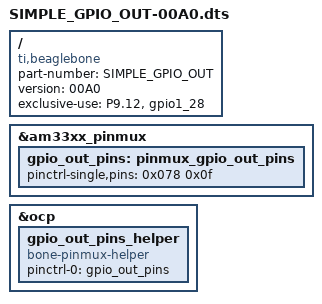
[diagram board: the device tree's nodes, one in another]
/*
 * Copyright (C) 2013
 *
 * This program is free software; you can redistribute it and/or modify
 * it under the terms of the GNU General Public License version 2 as
 * published by the Free Software Foundation.
 *
 * Simple GPIO overlay example: Configures pin P9.12 (gpio1_28) as an output pin
 */
/dts-v1/;
/plugin/;

/ {
    compatible = "ti,beaglebone", "ti,beaglebone-black";

    /* identification */
    part-number = "SIMPLE_GPIO_OUT";
    version = "00A0";

    /* state the resources this cape uses */
    exclusive-use =
        /* the pin header uses */
        "P9.12",/* conf_gpmc_ben1 gpio1_28 */
        /* the hardware ip uses */
        "gpio1_28";

    fragment@0 {
        /* pin mux offsets given to the am33xx_pinmux target are expected to be
           rooted at the base from where the conf_<module>_<pin> register starts
           which is 0x800. Therefore, 0x800 should be subtracted from the values
           given in the technical reference manual */
        target = <&am33xx_pinmux>;
        __overlay__ {
            gpio_out_pins: pinmux_gpio_out_pins {
                pinctrl-single,pins = <
                    0x078 0x0f /* P9.12, conf_gpmc_ben1, gpio1_28  | OUTPUT PULL UP/DOWN DISABLED MODE 7*/
                 >;
            };
        };
    };

    fragment@1 {
        target = <&ocp>;
        __overlay__ {
            gpio_out_pins_helper {
                compatible = "bone-pinmux-helper";
                pinctrl-names = "default";
                pinctrl-0 = <&gpio_out_pins>;
                status = "okay";
            };
        };
    };
};
